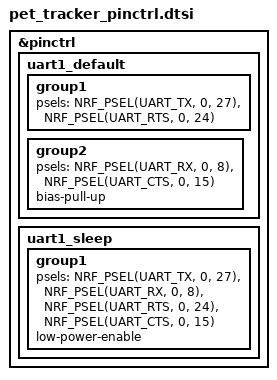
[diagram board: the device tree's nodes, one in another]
&pinctrl {
	uart1_default: uart1_default {
		group1 {
			psels = <NRF_PSEL(UART_TX, 0, 27)>,
				<NRF_PSEL(UART_RTS, 0, 24)>;
		};
		group2 {
			psels = <NRF_PSEL(UART_RX, 0, 8)>,
				<NRF_PSEL(UART_CTS, 0, 15)>;
			bias-pull-up;
		};
	};

	uart1_sleep: uart1_sleep {
		group1 {
			psels = <NRF_PSEL(UART_TX, 0, 27)>,
				<NRF_PSEL(UART_RX, 0, 8)>,
				<NRF_PSEL(UART_RTS, 0, 24)>,
				<NRF_PSEL(UART_CTS, 0, 15)>;
			low-power-enable;
		};
	};

	// uart0_defualt: uart0_defualt {
	// 	group1 {
	// 		psels = <NRF_PSEL(UART_TX, 1, 12)>, 
	// 				<NRF_PSEL(UART_RX, 1, 14)>;
	// 	};
	// };
};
